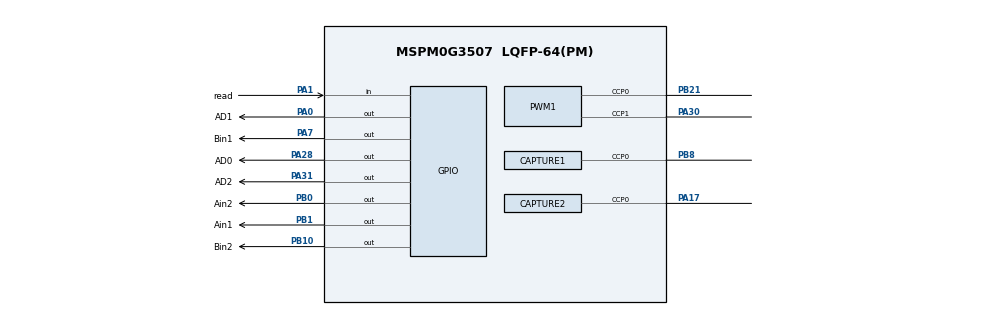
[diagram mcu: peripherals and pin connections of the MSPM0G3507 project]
/**
 * These arguments were used when this file was generated. They will be automatically applied on subsequent loads
 * via the GUI or CLI. Run CLI with '--help' for additional information on how to override these arguments.
 * @cliArgs --device "MSPM0G350X" --part "Default" --package "LQFP-64(PM)" --product "mspm0_sdk@2.10.00.04"
 * @v2CliArgs --device "MSPM0G3507" --package "LQFP-64(PM)" --product "mspm0_sdk@2.10.00.04"
 * @versions {"tool":"1.26.2+4477"}
 */

/**
 * Import the modules used in this configuration.
 */
const CAPTURE  = scripting.addModule("/ti/driverlib/CAPTURE", {}, false);
const CAPTURE1 = CAPTURE.addInstance();
const CAPTURE2 = CAPTURE.addInstance();
const GPIO     = scripting.addModule("/ti/driverlib/GPIO", {}, false);
const GPIO1    = GPIO.addInstance();
const GPIO2    = GPIO.addInstance();
const GPIO3    = GPIO.addInstance();
const GPIO4    = GPIO.addInstance();
const PWM      = scripting.addModule("/ti/driverlib/PWM", {}, false);
const PWM1     = PWM.addInstance();
const SYSCTL   = scripting.addModule("/ti/driverlib/SYSCTL");
const UART     = scripting.addModule("/ti/driverlib/UART", {}, false);
const UART1    = UART.addInstance();

/**
 * Write custom configuration values to the imported modules.
 */
CAPTURE1.$name                              = "LMotor";
CAPTURE1.captFilter                         = true;
CAPTURE1.peripheral.$assign                 = "TIMA0";
CAPTURE1.peripheral.ccp0Pin.$assign         = "PB8";
CAPTURE1.ccp0PinConfig.hideOutputInversion  = scripting.forceWrite(false);
CAPTURE1.ccp0PinConfig.onlyInternalResistor = scripting.forceWrite(false);
CAPTURE1.ccp0PinConfig.passedPeripheralType = scripting.forceWrite("Digital");
CAPTURE1.ccp0PinConfig.$name                = "ti_driverlib_gpio_GPIOPinGeneric4";

const Board = scripting.addModule("/ti/driverlib/Board", {}, false);

CAPTURE2.$name                              = "RMotor";
CAPTURE2.peripheral.$assign                 = "TIMA1";
CAPTURE2.peripheral.ccp0Pin.$assign         = "PA17";
CAPTURE2.ccp0PinConfig.hideOutputInversion  = scripting.forceWrite(false);
CAPTURE2.ccp0PinConfig.onlyInternalResistor = scripting.forceWrite(false);
CAPTURE2.ccp0PinConfig.passedPeripheralType = scripting.forceWrite("Digital");
CAPTURE2.ccp0PinConfig.$name                = "ti_driverlib_gpio_GPIOPinGeneric5";

GPIO1.$name                         = "MotorLCtl";
GPIO1.associatedPins.create(2);
GPIO1.associatedPins[0].$name       = "Bin1";
GPIO1.associatedPins[0].pin.$assign = "PA7";
GPIO1.associatedPins[1].$name       = "Bin2";
GPIO1.associatedPins[1].pin.$assign = "PB10";

GPIO2.$name                         = "MotorRCtl";
GPIO2.associatedPins.create(2);
GPIO2.associatedPins[0].$name       = "Ain1";
GPIO2.associatedPins[0].pin.$assign = "PB1";
GPIO2.associatedPins[1].$name       = "Ain2";
GPIO2.associatedPins[1].pin.$assign = "PB0";

GPIO3.$name                         = "Gray";
GPIO3.port                          = "PORTA";
GPIO3.associatedPins.create(3);
GPIO3.associatedPins[0].$name       = "AD0";
GPIO3.associatedPins[0].pin.$assign = "PA28";
GPIO3.associatedPins[1].$name       = "AD1";
GPIO3.associatedPins[1].pin.$assign = "PA0";
GPIO3.associatedPins[2].$name       = "AD2";
GPIO3.associatedPins[2].pin.$assign = "PA31";

GPIO4.$name                         = "Grayread";
GPIO4.port                          = "PORTA";
GPIO4.associatedPins[0].$name       = "read";
GPIO4.associatedPins[0].direction   = "INPUT";
GPIO4.associatedPins[0].pin.$assign = "PA1";

PWM1.timerCount                         = 1600;
PWM1.timerStartTimer                    = true;
PWM1.pwmMode                            = "EDGE_ALIGN_UP";
PWM1.$name                              = "Motor";
PWM1.peripheral.$assign                 = "TIMG8";
PWM1.peripheral.ccp0Pin.$assign         = "PB21";
PWM1.peripheral.ccp1Pin.$assign         = "PA30";
PWM1.PWM_CHANNEL_0.$name                = "ti_driverlib_pwm_PWMTimerCC0";
PWM1.PWM_CHANNEL_1.$name                = "ti_driverlib_pwm_PWMTimerCC1";
PWM1.ccp0PinConfig.direction            = scripting.forceWrite("OUTPUT");
PWM1.ccp0PinConfig.hideOutputInversion  = scripting.forceWrite(false);
PWM1.ccp0PinConfig.onlyInternalResistor = scripting.forceWrite(false);
PWM1.ccp0PinConfig.passedPeripheralType = scripting.forceWrite("Digital");
PWM1.ccp0PinConfig.$name                = "ti_driverlib_gpio_GPIOPinGeneric0";
PWM1.ccp1PinConfig.direction            = scripting.forceWrite("OUTPUT");
PWM1.ccp1PinConfig.hideOutputInversion  = scripting.forceWrite(false);
PWM1.ccp1PinConfig.onlyInternalResistor = scripting.forceWrite(false);
PWM1.ccp1PinConfig.passedPeripheralType = scripting.forceWrite("Digital");
PWM1.ccp1PinConfig.$name                = "ti_driverlib_gpio_GPIOPinGeneric1";

SYSCTL.forceDefaultClkConfig = true;

UART1.$name             = "UART_0";
UART1.targetBaudRate    = 115200;
UART1.txPinConfig.$name = "ti_driverlib_gpio_GPIOPinGeneric2";
UART1.rxPinConfig.$name = "ti_driverlib_gpio_GPIOPinGeneric3";

/**
 * Pinmux solution for unlocked pins/peripherals. This ensures that minor changes to the automatic solver in a future
 * version of the tool will not impact the pinmux you originally saw.  These lines can be completely deleted in order to
 * re-solve from scratch.
 */
Board.peripheral.$suggestSolution          = "DEBUGSS";
Board.peripheral.swclkPin.$suggestSolution = "PA20";
Board.peripheral.swdioPin.$suggestSolution = "PA19";
SYSCTL.peripheral.$suggestSolution         = "SYSCTL";
UART1.peripheral.$suggestSolution          = "UART0";
UART1.peripheral.rxPin.$suggestSolution    = "PA11";
UART1.peripheral.txPin.$suggestSolution    = "PA10";
